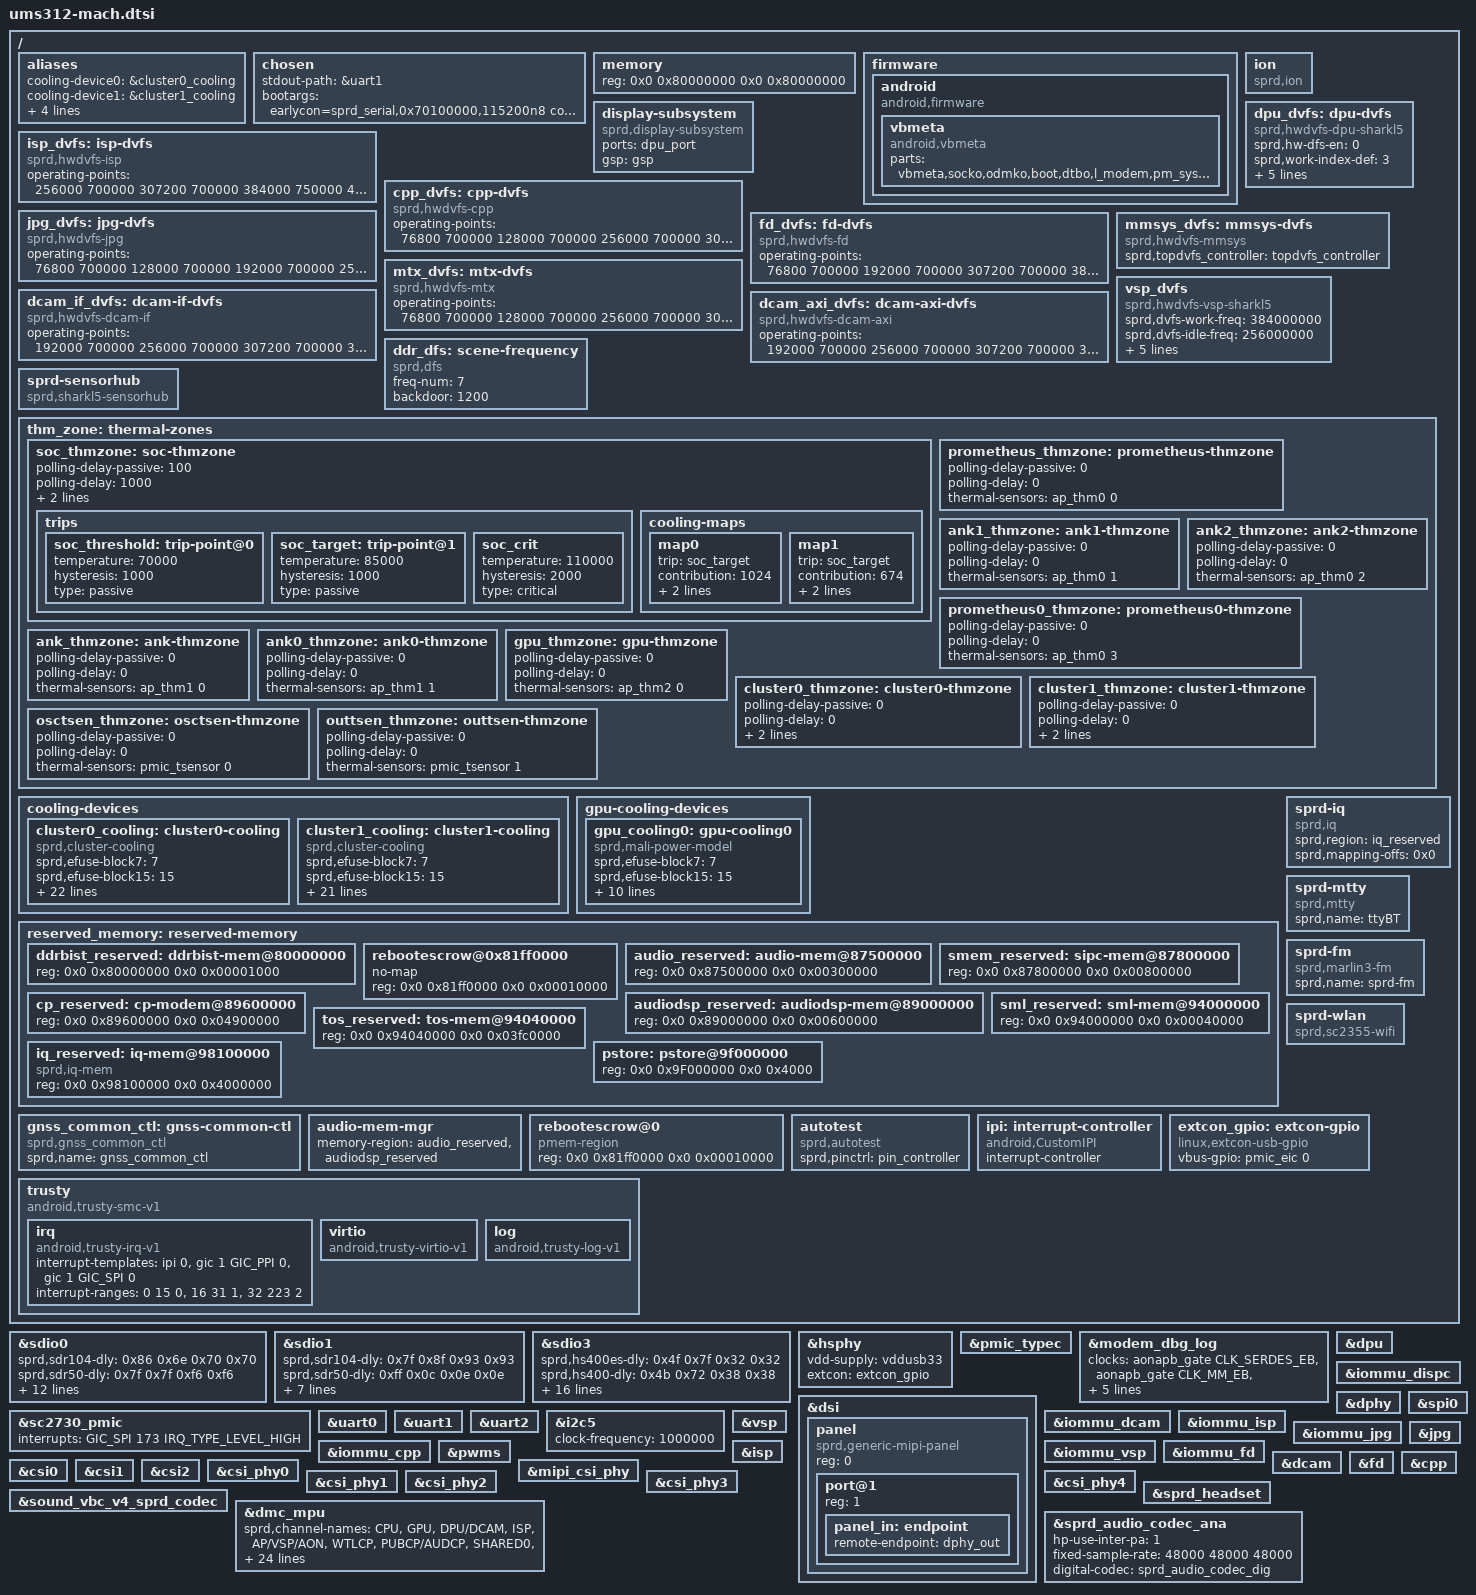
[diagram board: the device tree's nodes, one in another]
/*
 * Spreadtrum Sharkl5 board common DTS file
 *
 * Copyright (C) 2018, Spreadtrum Communications Inc.
 *
 * This file is licensed under a dual GPLv2 or X11 license.
 */

#include <dt-bindings/thermal/thermal.h>
/ {
	aliases {
		cooling-device0 = &cluster0_cooling;
		cooling-device1 = &cluster1_cooling;
		gpu-cooling0 = &gpu_cooling0;
		serial0 = &uart0;
		serial1 = &uart1;
		serial2 = &uart2;
	};

	chosen: chosen {
		stdout-path = &uart1;
		bootargs = "earlycon=sprd_serial,0x70100000,115200n8 console=ttyS1,115200n8 loglevel=1 init=/init root=/dev/ram0 ro rootwait swiotlb=1 printk.devkmsg=on androidboot.boot_devices=soc/soc:ap-apb/71400000.sdio";
	};

	memory: memory {
		device_type = "memory";
		reg = <0x0 0x80000000 0x0 0x80000000>;
	};

	firmware {
		android {
			compatible = "android,firmware";

			vbmeta {
				compatible = "android,vbmeta";
				parts = "vbmeta,socko,odmko,boot,dtbo,l_modem,pm_sys,l_ldsp,l_gdsp,l_agdsp,l_cdsp";
			};
		};
	};

	ion: ion {
		compatible = "sprd,ion";
		#address-cells = <1>;
		#size-cells = <0>;
	};

	display-subsystem {
		compatible = "sprd,display-subsystem";
		ports = <&dpu_port>;
		gsp = <&gsp>;
	};

	dpu_dvfs: dpu-dvfs {
		compatible = "sprd,hwdvfs-dpu-sharkl5";
		sprd,hw-dfs-en = <0>;
		sprd,work-index-def = <3>;
		sprd,idle-index-def = <1>;
		sprd,freq-upd-delay-en = <0>;
		sprd,freq-upd-hdsk-en = <1>;

		operating-points = <
			/* kHz    uV */
			153600    700000
			192000    700000
			256000    700000
			307200    700000
			384000    750000
			>;
	};
	isp_dvfs: isp-dvfs {
		compatible = "sprd,hwdvfs-isp";
		status = "disabled";
		operating-points = <
			/* kHz    uV */
			256000    700000
			307200    700000
			384000    750000
			468000    750000
			>;
	};

	cpp_dvfs: cpp-dvfs {
		compatible = "sprd,hwdvfs-cpp";
		status = "disabled";
		operating-points = <
			/* kHz    uV */
			76800     700000
			128000    700000
			256000    700000
			307200    750000
			>;
	};

	jpg_dvfs: jpg-dvfs {
		compatible = "sprd,hwdvfs-jpg";
		status = "disabled";
		operating-points = <
			/* kHz    uV */
			76800     700000
			128000    700000
			192000    700000
			256000    750000
			>;
	};

	fd_dvfs: fd-dvfs {
		compatible = "sprd,hwdvfs-fd";
		status = "disabled";
		operating-points = <
			/* kHz    uV */
			76800     700000
			192000    700000
			307200    700000
			384000    750000
			>;
	};

	mtx_dvfs: mtx-dvfs {
		compatible = "sprd,hwdvfs-mtx";
		status = "disabled";
		operating-points = <
			/* kHz    uV */
			76800     700000
			128000    700000
			256000    700000
			307200    700000
			384000    750000
			468000    750000
			>;
	};

	dcam_if_dvfs: dcam-if-dvfs {
		compatible = "sprd,hwdvfs-dcam-if";
		status = "disabled";
		operating-points = <
			/* kHz    uV */
			192000    700000
			256000    700000
			307200    700000
			384000    750000
			>;
	};
	dcam_axi_dvfs: dcam-axi-dvfs {
		compatible = "sprd,hwdvfs-dcam-axi";
		status = "disabled";
		operating-points = <
			/* kHz    uV */
			192000    700000
			256000    700000
			307200    700000
			384000    750000
			>;
	};
	mmsys_dvfs: mmsys-dvfs {
		compatible = "sprd,hwdvfs-mmsys";
		status = "disabled";
		sprd,topdvfs_controller = <&topdvfs_controller>;
	};

	vsp_dvfs: vsp_dvfs {
		compatible = "sprd,hwdvfs-vsp-sharkl5";
		sprd,dvfs-work-freq = <384000000>;
		sprd,dvfs-idle-freq = <256000000>;
		sprd,dvfs-enable-flag = <1>;
		sprd,freq-upd-delay-en = <0>;
		sprd,freq-upd-hdsk-en = <1>;

		operating-points = <
			/* kHz    uV */
			256000    700000
			307200    700000
			384000    750000
			>;
	};

	ddr_dfs: scene-frequency {
		compatible = "sprd,dfs";
		freq-num = <7>;
		backdoor = <1200>;
	};

	sprd-sensorhub {
		compatible = "sprd,sharkl5-sensorhub", "sprd,sensor-hub";
	};

	thm_zone: thermal-zones {

		soc_thmzone: soc-thmzone {
			polling-delay-passive = <100>;
			polling-delay = <1000>;
			sustainable-power = <2386>;
			thermal-sensors = <&soc_sensor  17>;
			trips {
				soc_threshold: trip-point@0 {
					temperature = <70000>;
					hysteresis = <1000>;
					type = "passive";
				};
				soc_target: trip-point@1 {
					temperature = <85000>;
					hysteresis = <1000>;
					type = "passive";
				};
				soc_crit: soc_crit {
					temperature = <110000>;
					hysteresis = <2000>;
					type = "critical";
				};
			};
			cooling-maps {
				map0 {
					trip = <&soc_target>;
					contribution = <1024>;
					cooling-device =
					<&cluster0_cooling THERMAL_NO_LIMIT \
					THERMAL_NO_LIMIT>;
				};
				map1 {
					trip = <&soc_target>;
					contribution = <674>;
					cooling-device =
					<&cluster1_cooling THERMAL_NO_LIMIT \
					THERMAL_NO_LIMIT>;
				};
			};
		};

		prometheus_thmzone: prometheus-thmzone {
			polling-delay-passive = <0>;
			polling-delay = <0>;
			thermal-sensors = <&ap_thm0 0>;
		};

		ank1_thmzone: ank1-thmzone {
			polling-delay-passive = <0>;
			polling-delay = <0>;
			thermal-sensors = <&ap_thm0 1>;
		};

		ank2_thmzone: ank2-thmzone {
			polling-delay-passive = <0>;
			polling-delay = <0>;
			thermal-sensors = <&ap_thm0 2>;
		};

		prometheus0_thmzone: prometheus0-thmzone {
			polling-delay-passive = <0>;
			polling-delay = <0>;
			thermal-sensors = <&ap_thm0 3>;
		};

		ank_thmzone: ank-thmzone {
			polling-delay-passive = <0>;
			polling-delay = <0>;
			thermal-sensors = <&ap_thm1 0>;
		};

		ank0_thmzone: ank0-thmzone {
			polling-delay-passive = <0>;
			polling-delay = <0>;
			thermal-sensors = <&ap_thm1 1>;
		};

		gpu_thmzone: gpu-thmzone {
			polling-delay-passive = <0>;
			polling-delay = <0>;
			thermal-sensors = <&ap_thm2 0>;
		};

		cluster0_thmzone: cluster0-thmzone {
			polling-delay-passive = <0>;
			polling-delay = <0>;
			sustainable-power = <2000>;
			thermal-sensors = <&cluster0_sensor  15>;
		};

		cluster1_thmzone: cluster1-thmzone {
			polling-delay-passive = <0>;
			polling-delay = <0>;
			sustainable-power = <2000>;
			thermal-sensors = <&cluster1_sensor  16>;
		};

		osctsen_thmzone: osctsen-thmzone {
			polling-delay-passive = <0>;
			polling-delay = <0>;
			thermal-sensors = <&pmic_tsensor 0>;
		};

		outtsen_thmzone: outtsen-thmzone {
			polling-delay-passive = <0>;
			polling-delay = <0>;
			thermal-sensors = <&pmic_tsensor 1>;
		};
	};

	cooling-devices {
		cluster0_cooling: cluster0-cooling {
			compatible = "sprd,cluster-cooling";
			#cooling-cells = <2>; /* min followed by max */
			sprd,efuse-block7 = <7>;
			sprd,efuse-block15 = <15>;
			/* core_leak =                             */
			/*(LIT_LEAK[4:0]+1) x 2mA x 0.85V x 18.69% */
			sprd,leak-core = <2 85 1869>;
			/* cluster_leak =                           */
			/* (LIT_LEAK[4:0]+1) x 2mA x 0.85V x 25.24% */
			sprd,leak-cluster = <2 85 2524>;
			/*core Tscale = aT^3 + bT^2 + cT +di   */
			sprd,core-temp-scale =
			/* a*10^7   b*10^7      c*10^7     d*10^7 */
			<  31      (-3041)      170000    (-1590000)>;
			/*core Vscale = eV^3 + fV^2 + gV + h */
			sprd,core-voltage-scale =
			/* e*10^2   f*10^2     g*10^2  h*10^2*/
			<  3320     (-7489)      5692      (-1423)>;
			/*cluster Tscale = aT^3 + bT^2 + cT +di   */
			sprd,cluster-temp-scale =
			/* a*10^7   b*10^7      c*10^7     d*10^7 */
			<  31      (-3041)      170000    (-1590000)>;
			/*cluster Vscale = eV^3 + fV^2 + gV + h */
			sprd,cluster-voltage-scale =
			/* e*10^2   f*10^2     g*10^2  h*10^2*/
			<  3320     (-7489)      5692      (-1423)>;
			sprd,efuse-switch = <0>;
			sprd,hotplug-period = <10>;
			sprd,min-cpufreq = <768000>;
			sprd,min-cpunum = <3>;
			sprd,core-base = <3930>;
			sprd,cluster-base = <1673>;
			sprd,dynamic-core =
			/*Pdynperghz*10    Freq     Vbase  */
			< 1084           1000     1000>;
			sprd,dynamic-cluster =
			/*Pdynperghz*10    Freq     Vbase  */
			< 757           1000     1000>;
			sprd,sensor-names = "ank0-thmzone","ank1-thmzone","ank2-thmzone";
			sprd,cii-per-core-tp = <100000 95000 90000>;
			sprd,cii-max-tp-core = <90000>;
		};

		cluster1_cooling: cluster1-cooling {
			compatible = "sprd,cluster-cooling";
			#cooling-cells = <2>; /* min followed by max */
			sprd,efuse-block7 = <7>;
			sprd,efuse-block15 = <15>;
			/* core_leak =                             */
			/*(LIT_LEAK[4:0]+1) x 2mA x 0.85V x 18.69% */
			sprd,leak-core = <8 85 1984>;
			/* cluster_leak =                           */
			/* (LIT_LEAK[4:0]+1) x 2mA x 0.85V x 25.24% */
			sprd,leak-cluster = <8 85 2064>;
			/*core Tscale = aT^3 + bT^2 + cT +d  */
			sprd,core-temp-scale =
			/* a*10^7   b*10^7	c*10^7	   d*10^7*/
			<  31      (-3041)      170000    (-1590000)>;
			/* core  Vscale = eV^3 + fV^2 + gV + h */
			sprd,core-voltage-scale =
			/* e*10^2  f*10^2     g*10^2  h*10^2*/
			<  3320     (-7489)      5692      (-1423)>;
			/*cluster Tscale = aT^3 + bT^2 + cT +di   */
			sprd,cluster-temp-scale =
			/* a*10^7   b*10^7      c*10^7     d*10^7 */
			<  31      (-3041)      170000    (-1590000)>;
			/*cluster Vscale = eV^3 + fV^2 + gV + h */
			sprd,cluster-voltage-scale =
			/* e*10^2   f*10^2     g*10^2  h*10^2*/
			<  3320     (-7489)      5692      (-1423)>;
			sprd,efuse-switch = <0>;
			sprd,hotplug-period = <10>;
			sprd,min-cpufreq = <1228800>;
			sprd,min-cpunum = <0>;
			sprd,core-base = <11464>;
			sprd,cluster-base = <1673>;
			sprd,dynamic-core =
			/* Pdynperghz*10    Freq     Vbase */
			<  4895          1000     1000>;
			sprd,dynamic-cluster =
			/* Pdynperghz*10    Freq     Vbase */
			<  757            1000     1000>;
			sprd,sensor-names = "prometheus0-thmzone";
			sprd,cii-per-core-tp = <90000>;
			sprd,cii-max-tp-core = <90000>;
		};
	};

	gpu-cooling-devices {
		gpu_cooling0: gpu-cooling0 {
			compatible = "sprd,mali-power-model";
			#cooling-cells = <2>;
			sprd,efuse-block7 = <7>;
			sprd,efuse-block15 = <15>;
			/* core_leak =                             */
			/*(LIT_LEAK[4:0]+1) x 2mA x 0.85V x 18.69% */
			sprd,leak-core = <2 85 1869>;
			/* cluster_leak =                           */
			/* (LIT_LEAK[4:0]+1) x 2mA x 0.85V x 25.24% */
			sprd,leak-cluster = <2 85 2524>;
			/*Tscale = aT^3 + bT^2 + cT +di   */
			sprd,temp-scale =
			/* a*10^7   b*10^7      c*10^7     d*10^7 */
			<  300     (-29000)     1491000    (-13962000)>;
			/*Vscale = eV^3 + fV^2 + gV + h */
			sprd,voltage-scale =
			/* e*10^2   f*10^2     g*10^2      h*10^2*/
			<  (-1629)  6627       (-6871)     2222>;
			sprd,hotplug-period = <0>;
			sprd,core-base = <966>;
			sprd,cluster-base = <966>;
			sprd,dynamic-core =
			/*Pdynperghz    Freq     Vbase  */
			< 6046           768     900>;
			sprd,dynamic-cluster =
			/*Pdynperghz    Freq     Vbase  */
			< 6064           768     900>;
		};
	};

	reserved_memory: reserved-memory {
		#address-cells = <2>;
		#size-cells = <2>;
		ranges;

		ddrbist_reserved: ddrbist-mem@80000000{
			reg = <0x0 0x80000000 0x0 0x00001000>;
		};

		rebootescrow@0x81ff0000 {
			no-map;
			reg = <0x0 0x81ff0000 0x0 0x00010000>; /* 64K */
		};

		audio_reserved: audio-mem@87500000{
			reg = <0x0 0x87500000 0x0 0x00300000>;
		};

		smem_reserved: sipc-mem@87800000{
			reg = <0x0 0x87800000 0x0 0x00800000>;
		};

		audiodsp_reserved: audiodsp-mem@89000000 {
			reg = <0x0 0x89000000 0x0 0x00600000>;
		};

		cp_reserved: cp-modem@89600000 {
			reg = <0x0 0x89600000 0x0 0x04900000>;
		};

		/* must be 64M aligned */
		sml_reserved: sml-mem@94000000{
			reg = <0x0 0x94000000 0x0 0x00040000>;
		};

		tos_reserved: tos-mem@94040000{
			reg = <0x0 0x94040000 0x0 0x03fc0000>;
		};

		/* Only used for iq, will be removed in normal mode by uboot */
		iq_reserved: iq-mem@98100000{
			compatible = "sprd,iq-mem";
			reg = <0x0 0x98100000 0x0 0x4000000>;
		};

		pstore: pstore@9f000000{
			reg = <0x0 0x9F000000 0x0 0x4000>;
		};

	};

	sprd-iq {
		compatible = "sprd,iq";
		sprd,region = <&iq_reserved>;
		sprd,mapping-offs = <0x0>;
	};

	sprd-mtty {
		compatible = "sprd,mtty";
		sprd,name = "ttyBT";
	};

	sprd-fm {
		compatible = "sprd,marlin3-fm";
		sprd,name = "sprd-fm";
	};

	sprd-wlan {
		compatible = "sprd,sc2355-wifi";
	};

	gnss_common_ctl:gnss-common-ctl {
		compatible = "sprd,gnss_common_ctl";
		sprd,name = "gnss_common_ctl";
	};

	audio-mem-mgr {
		memory-region = <&audio_reserved &audiodsp_reserved>;
	};

	rebootescrow@0 {
		compatible = "pmem-region";
		reg = <0x0 0x81ff0000 0x0 0x00010000>;
	};

	autotest: autotest {
		compatible = "sprd,autotest";
		sprd,pinctrl = <&pin_controller>;
	};

	ipi: interrupt-controller {
		compatible = "android,CustomIPI";
		#interrupt-cells = <1>;
		interrupt-controller;
	};

	trusty {
		compatible = "android,trusty-smc-v1";
		irq {
			compatible = "android,trusty-irq-v1";
			interrupt-templates = <&ipi 0>,
						<&gic 1 GIC_PPI 0>,
						<&gic 1 GIC_SPI 0>;
				interrupt-ranges = < 0  15 0>,
						<16  31 1>,
						<32 223 2>;
		};

		virtio {
			compatible = "android,trusty-virtio-v1";
		};

		log {
			compatible = "android,trusty-log-v1";
		};
	};

	extcon_gpio: extcon-gpio {
		compatible = "linux,extcon-usb-gpio";
		vbus-gpio = <&pmic_eic 0 GPIO_ACTIVE_HIGH>;
	};

};

&sdio0 {
	sprd,sdr104-dly = <0x86 0x6e 0x70 0x70>;
	sprd,sdr50-dly = <0x7f 0x7f 0xf6 0xf6>;
	sprd,sdhs-dly = <0x0 0x24 0x24 0x24>;
	sprd,legacy-dly = <0x0 0x24 0x24 0x24>;
	vmmc-supply = <&vddsdcore>;
	vqmmc-supply = <&vddsdio>;
	voltage-ranges = <3000 3000>;
	bus-width = <4>;
	sd-uhs-sdr104;
	sd-uhs-sdr50;
	sprd,name = "sdio_sd";
	sprd,sdio-adma;
	no-sdio;
	no-mmc;
	status = "okay";
};

&sdio1 {
	sprd,sdr104-dly = <0x7f 0x8f 0x93 0x93>;
	sprd,sdr50-dly = <0xff 0x0c 0x0e 0x0e>;
	sd-uhs-sdr104;
	sd-uhs-sdr50;
	bus-width = <4>;
	sprd,name = "sdio_wifi";
	sprd,sdio-adma;
	no-sd;
	no-mmc;
	status = "okay";
};

&sdio3 {
	sprd,hs400es-dly = <0x4f 0x7f 0x32 0x32>;
	sprd,hs400-dly = <0x4b 0x72 0x38 0x38>;
	sprd,hs200-dly = <0x7f 0xde 0xca 0xca>;
	sprd,ddr52-dly = <0x30 0x27 0x19 0x19>;
	sprd,mmchs-dly = <0x7f 0x94 0x7f 0x7f>;
	vmmc-supply = <&vddemmccore>;
	voltage-ranges = <3000 3000>;
	bus-width = <8>;
	non-removable;
	cap-mmc-hw-reset;
	mmc-hs400-enhanced-strobe;
	mmc-hs400-1_8v;
	mmc-hs200-1_8v;
	mmc-ddr-1_8v;
	sprd,name = "sdio_emmc";
	sprd,sdio-adma;
	no-sdio;
	no-sd;
	status = "okay";
};

&hsphy {
	vdd-supply = <&vddusb33>;
	extcon = <&extcon_gpio>;
};

&pmic_typec {
	status = "okay";
};

&modem_dbg_log {
	status = "okay";
	clock-names = "serdes_eb", "mm_eb", "ana_eb", "dphy_cfg_eb", "dphy_ref_eb", "dsi_csi_test_eb", "cphy_cfg_eb";
	clocks = <&aonapb_gate CLK_SERDES_EB>, <&aonapb_gate CLK_MM_EB>, <&aonapb_gate CLK_ANA_EB>,
     <&aonapb_gate CLK_SDPHY_CFG_EB>, <&aonapb_gate CLK_SDPHY_REF_EB>, <&aonapb_gate CLK_DSI_CSI_TEST_EB>, <&aonapb_gate CLK_CPHY_CFG_EN>;
};

&sc2730_pmic {
	interrupts = <GIC_SPI 173 IRQ_TYPE_LEVEL_HIGH>;
};

&dpu {
	status = "okay";
};

&iommu_dispc {
	status = "okay";
};

&dsi {
	status = "okay";
	#address-cells = <1>;
	#size-cells = <0>;

	panel: panel {
		compatible = "sprd,generic-mipi-panel";
		#address-cells = <1>;
		#size-cells = <0>;
		reg = <0>;

		port@1 {
			reg = <1>;
			panel_in: endpoint {
				remote-endpoint = <&dphy_out>;
			};
		};
	};
};

&dphy {
	status = "okay";
};

&uart0 {
	status = "okay";
};

&uart1 {
	status = "okay";
};

&uart2 {
	status = "okay";
};

&i2c5 {
	status = "okay";
	clock-frequency = <1000000>;
};

&spi0 {
	/*used for fingerprint sensor*/
	status = "okay";
};

&iommu_dcam{
	status = "okay";
};

&iommu_isp{
	status = "okay";
};

&iommu_jpg{
	status = "okay";
};

&iommu_cpp{
	status = "okay";
};

&iommu_vsp{
	status = "okay";
};

&iommu_fd{
	status = "okay";
};

&pwms {
	status = "okay";
};

&vsp {
	status = "okay";
};

&jpg {

	status = "okay";
};

&dcam {
	status = "okay";
};

&isp {
	status = "okay";
};

&fd {
	status = "okay";
};

&cpp {
	status = "okay";
};

&csi0 {
	status = "okay";
};

&csi1 {
	status = "okay";
};

&csi2 {
	status = "okay";
};

&mipi_csi_phy {
	status = "okay";
};

&csi_phy0{
	status = "okay";
};

&csi_phy1{
	status = "okay";
};

&csi_phy2{
	status = "okay";
};

&csi_phy3{
	status = "okay";
};

&csi_phy4{
	status = "okay";
};

&sprd_headset {
	status = "okay";
};

&sound_vbc_v4_sprd_codec {
	status = "okay";
};
&isp_dvfs {
	status = "okay";
};
&cpp_dvfs {
	status = "okay";
};
&jpg_dvfs {
	status = "okay";
};
&fd_dvfs {
	status = "okay";
};
&mtx_dvfs {
	status = "okay";
};
&dcam_if_dvfs {
	status = "okay";
};
&dcam_axi_dvfs {
	status = "okay";
};
&mmsys_dvfs {
	status = "okay";
};

&dmc_mpu {
	status = "okay";
	sprd,channel-names =
		"CPU", "GPU", "DPU/DCAM","ISP",
		"AP/VSP/AON", "WTLCP", "PUBCP/AUDCP",
		"SHARED0", "SHARED1", "SHARED2",
		"SHARED3", "SHARED4", "SHARED5",
		"SHARED6", "SHARED7", "SHARED8";
	sprd,ranges = <0 0 0 0>, <0 0 0 0>, <0 0 0 0>,
		<0 0 0 0>, <0 0 0 0>, <0 0x87400000 0 0x9c100000>,
		<0 0x87400000 0 0x9c100000>, <0 0 0 0>, <0 0 0 0>,
		<0 0 0 0>, <0 0 0 0>, <0 0 0 0>,
		<0 0 0 0>, <0 0 0 0>, <0 0 0 0>,
		<0 0 0 0>;
	sprd,chn-config =
		<DISABLE MON_INSIDE MON_WRITE>,
		<DISABLE MON_INSIDE MON_WRITE>,
		<DISABLE MON_INSIDE MON_WRITE>,
		<DISABLE MON_INSIDE MON_WRITE>,
		<DISABLE MON_INSIDE MON_WRITE>,
		<ENABLE MON_OUTSIDE MON_WRITE>,
		<ENABLE MON_OUTSIDE MON_WRITE>,
		<DISABLE MON_INSIDE MON_WRITE>,
		<DISABLE MON_INSIDE MON_WRITE>,
		<DISABLE MON_INSIDE MON_WRITE>,
		<DISABLE MON_INSIDE MON_WRITE>,
		<DISABLE MON_INSIDE MON_WRITE>,
		<DISABLE MON_INSIDE MON_WRITE>,
		<DISABLE MON_INSIDE MON_WRITE>,
		<DISABLE MON_INSIDE MON_WRITE>,
		<DISABLE MON_INSIDE MON_WRITE>;
	sprd,panic;
};

&sprd_audio_codec_ana {
	status = "okay";
	hp-use-inter-pa = <1>;
	fixed-sample-rate = <48000 48000 48000>;
	digital-codec = <&sprd_audio_codec_dig>;
};
